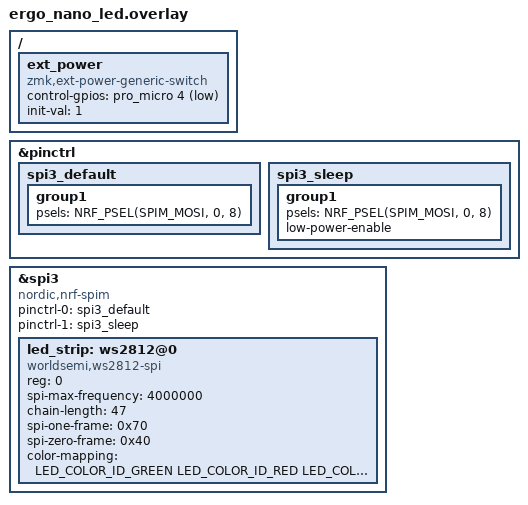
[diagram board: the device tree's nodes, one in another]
/*
 * Ergo-Nano LED Shield Overlay
 * Enables WS2812 RGB LED strip (38 per-key + 9 underglow = 47 total) on P0
 * and external power control for P-channel MOSFET gate on P4.
 */

#include <dt-bindings/led/led.h>
#include <dt-bindings/zmk/ext_power.h>

&pinctrl {
    /* SPI3 MOSI on P0.08 (pro_micro 0) for WS2812 serial data */
    spi3_default: spi3_default {
        group1 {
            psels = <NRF_PSEL(SPIM_MOSI, 0, 8)>;
        };
    };

    spi3_sleep: spi3_sleep {
        group1 {
            psels = <NRF_PSEL(SPIM_MOSI, 0, 8)>;
            low-power-enable;
        };
    };
};

&spi3 {
    compatible = "nordic,nrf-spim";
    status = "okay";
    pinctrl-0 = <&spi3_default>;
    pinctrl-1 = <&spi3_sleep>;
    pinctrl-names = "default", "sleep";

    led_strip: ws2812@0 {
        compatible = "worldsemi,ws2812-spi";
        reg = <0>;
        spi-max-frequency = <4000000>;

        /* 38 per-key LEDs + 9 underglow LEDs = 47 total LEDs */
        chain-length = <47>;
        spi-one-frame = <0x70>;
        spi-zero-frame = <0x40>;
        color-mapping = <LED_COLOR_ID_GREEN
                         LED_COLOR_ID_RED
                         LED_COLOR_ID_BLUE>;
    };
};

/ {
    /* Control P-MOSFET gate on P4 (pro_micro 4) to gate power to the LED array */
    ext_power {
        compatible = "zmk,ext-power-generic-switch";
        control-gpios = <&pro_micro 4 GPIO_ACTIVE_LOW>;
        init-val = <1>;
    };
};
